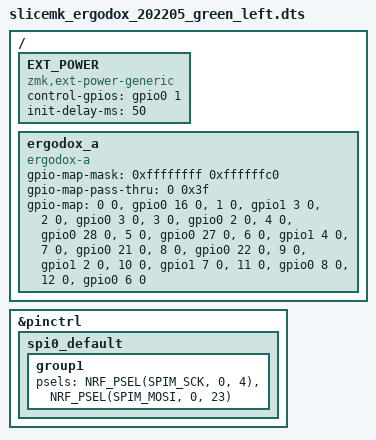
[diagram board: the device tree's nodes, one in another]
/dts-v1/;
#include "slicemk_ergodox_202205_green_common.dts"

/ {
    EXT_POWER {
        compatible = "zmk,ext-power-generic";
        control-gpios = <&gpio0 1 GPIO_ACTIVE_HIGH>;
        init-delay-ms = <50>;
    };

    ergodox_a: ergodox_a {
        compatible = "ergodox-a";
        #gpio-cells = <2>;
        gpio-map-mask = <0xffffffff 0xffffffc0>;
        gpio-map-pass-thru = <0 0x3f>;
        gpio-map =
            <0 0 &gpio0 16 0>,
            <1 0 &gpio1 3 0>,
            <2 0 &gpio0 3 0>,
            <3 0 &gpio0 2 0>,
            <4 0 &gpio0 28 0>,
            <5 0 &gpio0 27 0>,
            <6 0 &gpio1 4 0>,
            <7 0 &gpio0 21 0>,
            <8 0 &gpio0 22 0>,
            <9 0 &gpio1 2 0>,
            <10 0 &gpio1 7 0>,
            <11 0 &gpio0 8 0>,
            <12 0 &gpio0 6 0>;
    };
};

&pinctrl {
    // Define an arbitrary unused pin for SCK as it's required for SPI. Define
    // MOSI pin for LED data.
    spi0_default: spi0_default {
        group1 {
            psels =
                <NRF_PSEL(SPIM_SCK, 0, 4)>,
                <NRF_PSEL(SPIM_MOSI, 0, 23)>;
        };
    };
};
